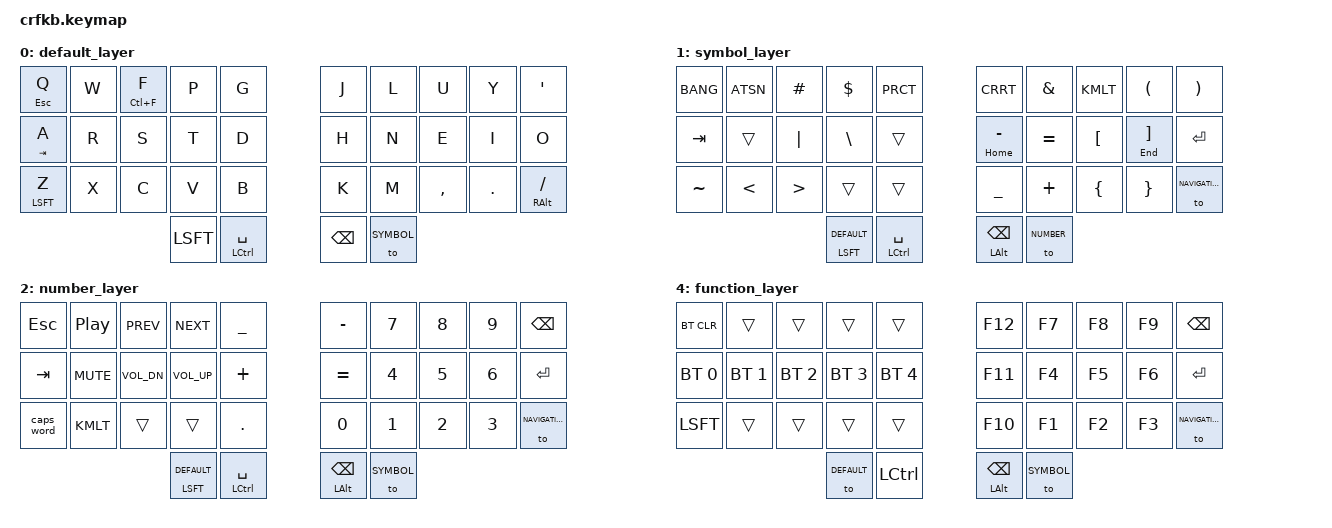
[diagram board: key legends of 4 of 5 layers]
/*
 * Copyright (c) 2020 The ZMK Contributors
 *
 * SPDX-License-Identifier: MIT
 */

#include <behaviors.dtsi>
#include <dt-bindings/zmk/keys.h>
#include <dt-bindings/zmk/bt.h>
#include <dt-bindings/zmk/outputs.h>
#include <dt-bindings/zmk/mouse.h>

#define DEFAULT 0
#define SYMBOL 1
#define NUMBER 2
#define NAVIGATION 3
#define FUNCTION 4

&caps_word {
    continue-list = <UNDERSCORE MINUS BACKSPACE>;
};

&mt {
  //  flavor = "tap-preferred";
   // tapping_term_ms = <200>;
};

&mmv {
    time-to-max-speed-ms = <500>;
};

&mwh {
    acceleration-exponent=<1>;
};

/ { 

    combos {
        compatible = "zmk,combos";
        combo_function {
            timeout-ms = <50>;
            key-positions = <30 33>;
            bindings = <&to FUNCTION>;
        };

        combo_esc {
            timeout-ms = <50>;
            key-positions = <0 1>;
            bindings = <&kp ESC>;
        };
        
         combo_tab {
            timeout-ms = <50>;
            key-positions = <10 11>;
            bindings = <&kp TAB>;
        };
        
        combo_ralt {
            timeout-ms = <50>;
            key-positions = <17 16>;
            bindings = <&kp RALT>;
        };
        
        combo_lalt {
            timeout-ms = <50>;
            key-positions = <11 12>;
            bindings = <&kp LALT>;
        };
        
        combo_lgui {
            timeout-ms = <50>;
            key-positions = <12 13>;
            bindings = <&kp LGUI>;
        };
        
        
        combo_rgui {
            timeout-ms = <50>;
            key-positions = <17 18>;
            bindings = <&kp RGUI>;
        };

        // symbol combos
        combo_semicolon {
            timeout-ms = <50>;
            key-positions = <8 9>;
            bindings = <&kp SEMICOLON>;
        };
        
    };

    behaviors {
     	td: tapdance {
        compatible = "zmk,behavior-hold-tap";
        label = "TAPDANCE";
        #binding-cells = <2>;
        tapping-term-ms = <190>;
        quick_tap_ms = <0>;
        flavor = "tap-preferred";
        bindings = <&kp>, <&kp>;
      };  
    };

    keymap {
        compatible = "zmk,keymap";
                
       	default_layer {
		bindings = <
			&td ESC Q      &kp W &td LC(F) F &kp P &kp G 	&kp J &kp L &kp U    &kp Y   &kp SINGLE_QUOTE 
			&td TAB A  &kp R &kp S &kp T &kp D 		&kp H &kp N &kp E    &kp I   &kp O
			&mt LSFT Z &kp X &kp C &kp V &kp B	      	&kp K &kp M &kp CMMA &kp DOT &mt RALT FSLH
          			&kp LSFT &mt LCTRL SPC  	&kp BSPC &to SYMBOL 
		>;
	};

       	symbol_layer {
		bindings = <
			&kp BANG  	    &kp ATSN      &kp HASH          &kp DLLR    &kp PRCT    	&kp CRRT  	&kp AMPS &kp KMLT &kp LPRN  	&kp RPRN 
			&kp TAB   	    &trans        &kp PIPE          &kp BSLH    &trans	  	&td HOME MINUS 	&kp EQL  &kp LBKT &td END RBKT  &kp RET 
			&kp TILDE &kp LESS_THAN &kp GREATER_THAN  &trans      &trans 	        &kp UNDER 	&kp PLUS &kp LBRC &kp RBRC  	&to NAVIGATION 
					 &mt LSFT DEFAULT &mt LCTRL SPC  		&mt LALT BSPC &to NUMBER 
		>;
	};
		
	number_layer {
		bindings = <
			&kp ESC    &kp C_PLAY_PAUSE &kp C_PREV    &kp C_NEXT    &kp UNDER      &kp MINUS &kp N7 &kp N8 &kp N9 &kp BSPC 
			&kp TAB    &kp C_MUTE       &kp C_VOL_DN  &kp C_VOL_UP  &kp PLUS	&kp EQL   &kp N4 &kp N5 &kp N6 &kp RET
			&caps_word &kp KMLT  &trans        &trans        &kp DOT       	&kp N0    &kp N1 &kp N2 &kp N3 &to NAVIGATION
					                &mt LSFT DEFAULT  &mt LCTRL SPC  	&mt LALT BSPC  &to SYMBOL 
		>;
	};	
		
	navigation_layer {
		bindings = <
			&td LA(F4) ESC  &mkp LCLK	&mmv MOVE_UP      &mkp RCLK          &mwh SCROLL_UP 		&kp LC(Y)       &kp LC(V)      &kp LC(C)    &kp LC(X)       &kp LC(Z)
			&kp TAB    	&mmv MOVE_LEFT  &mmv MOVE_DOWN    &mmv MOVE_RIGHT    &mwh SCROLL_DOWN  		&kp LEFT_ARROW  &kp DOWN_ARROW &kp UP_ARROW &kp RIGHT_ARROW &kp RET 
			&caps_word 	&trans      	&mwh SCROLL_LEFT  &mwh SCROLL_RIGHT  &trans   			&kp HOME        &kp PAGE_DOWN  &kp PAGE_UP  &kp END         &kp DEL   
					                                    &mt LSFT DEFAULT    &kp LCTRL SPC  		&mt LALT BSPC	&to SYMBOL 
		>;
	};	
  

   	function_layer {
		bindings = <
			&bt BT_CLR    &trans        &trans        &trans        &trans          	&kp F12 &kp F7 &kp F8 &kp F9 &kp BSPC 
			&bt BT_SEL 0  &bt BT_SEL 1  &bt BT_SEL 2  &bt BT_SEL 3  &bt BT_SEL 4 		&kp F11 &kp F4 &kp F5 &kp F6 &kp RET
			&kp LSFT      &trans        &trans        &trans        &trans			&kp F10 &kp F1 &kp F2 &kp F3 &to NAVIGATION
					                                    &to DEFAULT   &kp LCTRL  		  &mt LALT BSPC &to SYMBOL 
		>;
	};	
		    
     };
};
